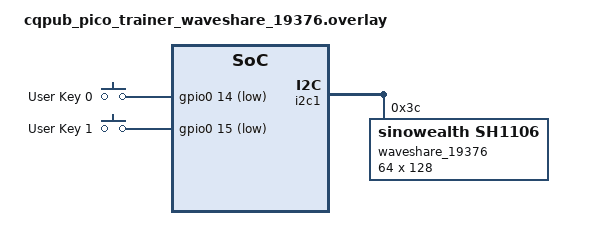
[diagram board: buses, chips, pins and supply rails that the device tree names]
#include "cqpub_pico_trainer.overlay"

/ {
	buttons {
		compatible = "gpio-keys";
		key0: key0 {
			gpios = <&gpio0 14 (GPIO_PULL_UP | GPIO_ACTIVE_LOW)>;
			label = "User Key 0";
			zephyr,code = <INPUT_KEY_0>;
		};
		key1: key1 {
			gpios = <&gpio0 15 (GPIO_PULL_UP | GPIO_ACTIVE_LOW)>;
			label = "User Key 1";
			zephyr,code = <INPUT_KEY_1>;
		};
	};

	chosen {
		zephyr,display = &waveshare_19376;
	};
};

&i2c1 {
	status = "okay";

	waveshare_19376: ssd1306@3c {
		compatible = "sinowealth,sh1106";
		status = "okay";
		reg = <0x3c>;
		width = <64>;
		height = <128>;
		segment-offset = <0>;
		page-offset = <0>;
		display-offset = <0x60>;
		multiplex-ratio = <63>;
		prechargep = <0x22>;
		ready-time-ms = <0>;
	};
};
